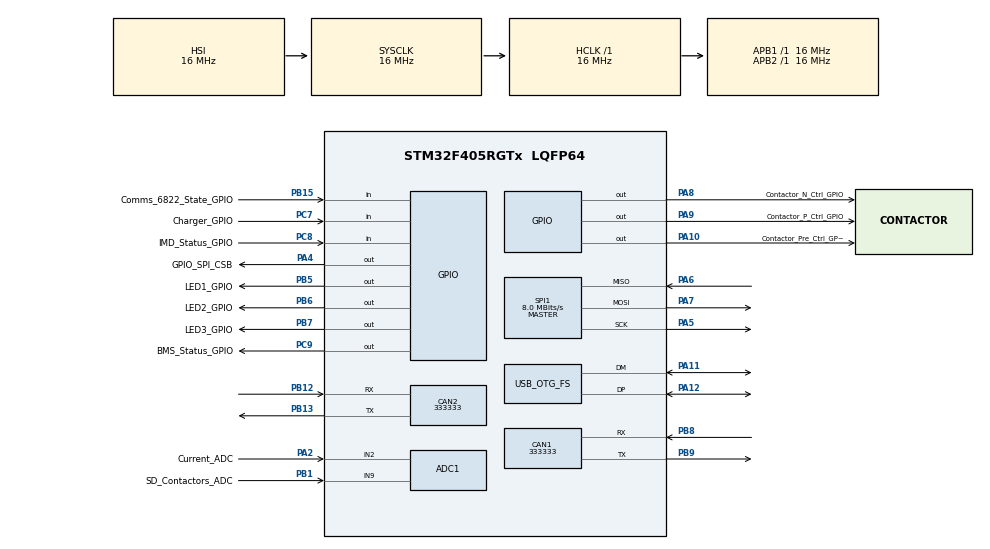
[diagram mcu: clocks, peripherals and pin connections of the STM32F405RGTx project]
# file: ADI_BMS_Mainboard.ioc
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ADC1.Channel-6\#ChannelRegularConversion=ADC_CHANNEL_2
ADC1.NbrOfConversionFlag=1
ADC1.Rank-6\#ChannelRegularConversion=1
ADC1.SamplingTime-6\#ChannelRegularConversion=ADC_SAMPLETIME_3CYCLES
ADC1.master=1
CAN1.CalculateBaudRate=333333
CAN1.CalculateTimeBit=3000
CAN1.CalculateTimeQuantum=1000.0
CAN2.CalculateBaudRate=333333
CAN2.CalculateTimeBit=3000
CAN2.CalculateTimeQuantum=1000.0
Mcu.Family=STM32F4
Mcu.Name=STM32F405RGTx
Mcu.Package=LQFP64
NVIC.OTG_FS_IRQn=true\:0\:0\:false\:false\:true\:false\:true\:true
NVIC.PriorityGroup=NVIC_PRIORITYGROUP_4
PA10.GPIO_Label=Contactor_Pre_Ctrl_GPIO
PA10.Signal=GPIO_Output
PA11.Mode=Device_Only
PA11.Signal=USB_OTG_FS_DM
PA12.Mode=Device_Only
PA12.Signal=USB_OTG_FS_DP
PA13.Mode=Trace_Asynchronous_SW
PA13.Signal=SYS_JTMS-SWDIO
PA14.Mode=Trace_Asynchronous_SW
PA14.Signal=SYS_JTCK-SWCLK
PA2.GPIO_Label=Current_ADC
PA2.Signal=ADCx_IN2
PA4.GPIO_Label=GPIO_SPI_CSB
PA4.Signal=GPIO_Output
PA5.Mode=Full_Duplex_Master
PA5.Signal=SPI1_SCK
PA6.Mode=Full_Duplex_Master
PA6.Signal=SPI1_MISO
PA7.Mode=Full_Duplex_Master
PA7.Signal=SPI1_MOSI
PA8.GPIO_Label=Contactor_N_Ctrl_GPIO
PA8.Signal=GPIO_Output
PA9.GPIO_Label=Contactor_P_Ctrl_GPIO
PA9.Signal=GPIO_Output
PB1.GPIO_Label=SD_Contactors_ADC
PB1.Signal=ADCx_IN9
PB12.Mode=CAN_Activate
PB12.Signal=CAN2_RX
PB13.Mode=CAN_Activate
PB13.Signal=CAN2_TX
PB15.GPIO_Label=Comms_6822_State_GPIO
PB15.Signal=GPIO_Input
PB3.Mode=Trace_Asynchronous_SW
PB3.Signal=SYS_JTDO-SWO
PB5.GPIO_Label=LED1_GPIO
PB5.Signal=GPIO_Output
PB6.GPIO_Label=LED2_GPIO
PB6.Signal=GPIO_Output
PB7.GPIO_Label=LED3_GPIO
PB7.Signal=GPIO_Output
PB8.Mode=CAN_Activate
PB8.Signal=CAN1_RX
PB9.Mode=CAN_Activate
PB9.Signal=CAN1_TX
PC7.GPIO_Label=Charger_GPIO
PC7.Signal=GPIO_Input
PC8.GPIO_Label=IMD_Status_GPIO
PC8.Signal=GPIO_Input
PC9.GPIO_Label=BMS_Status_GPIO
PC9.Signal=GPIO_Output
PH0-OSC_IN.Mode=HSE-External-Oscillator
PH0-OSC_IN.Signal=RCC_OSC_IN
PH1-OSC_OUT.Mode=HSE-External-Oscillator
PH1-OSC_OUT.Signal=RCC_OSC_OUT
ProjectManager.HeapSize=0x200
ProjectManager.StackSize=0x400
ProjectManager.TargetToolchain=STM32CubeIDE
RCC.48MHZClocksFreq_Value=48000000
RCC.AHBFreq_Value=16000000
RCC.APB1Freq_Value=16000000
RCC.APB2Freq_Value=16000000
RCC.CortexFreq_Value=16000000
RCC.HSE_VALUE=25000000
RCC.HSI_VALUE=16000000
RCC.LSE_VALUE=32768
RCC.PLLM=15
RCC.PLLN=144
RCC.PLLQ=5
RCC.SYSCLKFreq_VALUE=16000000
RCC.VCOOutputFreq_Value=240000000
SH.ADCx_IN2.0=ADC1_IN2,IN2
SH.ADCx_IN9.0=ADC1_IN9,IN9
SPI1.CalculateBaudRate=8.0 MBits/s
SPI1.Direction=SPI_DIRECTION_2LINES
SPI1.Mode=SPI_MODE_MASTER
SPI1.VirtualType=VM_MASTER
USB_DEVICE.CLASS_NAME_FS=CDC
USB_DEVICE.VirtualMode-CDC_FS=Cdc
USB_DEVICE.VirtualModeFS=Cdc_FS
USB_OTG_FS.VirtualMode=Device_Only
VP_TIM2_VS_ClockSourceINT.Mode=Internal
VP_USB_DEVICE_VS_USB_DEVICE_CDC_FS.Mode=CDC_FS
board=custom

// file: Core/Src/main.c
/* USER CODE BEGIN Header */
/**
  ******************************************************************************
  * @file           : main.c
  * @brief          : Main program body
  ******************************************************************************
  * @attention
  *
  * Copyright (c) 2025 STMicroelectronics.
  * All rights reserved.
  *
  * This software is licensed under terms that can be found in the LICENSE file
  * in the root directory of this software component.
  * If no LICENSE file comes with this software, it is provided AS-IS.
  *
  ******************************************************************************
  */
/* USER CODE END Header */
#include "main.h"
#include "usb_device.h"

/* USER CODE BEGIN Includes */
#include "adBms_Application.h"
#include "usbd_cdc_if.h"
// CDC_Transmit_FS((uint8_t *) txBuf, strlen(txBuf)); // transmit data over usb ie for putty or hterm

/* USER CODE END Includes */

ADC_HandleTypeDef hadc1;

CAN_HandleTypeDef hcan1;
CAN_HandleTypeDef hcan2;

SPI_HandleTypeDef hspi1;

TIM_HandleTypeDef htim2;

void SystemClock_Config(void);
static void MX_GPIO_Init(void);
static void MX_ADC1_Init(void);
static void MX_CAN1_Init(void);
static void MX_CAN2_Init(void);
static void MX_SPI1_Init(void);
static void MX_TIM2_Init(void);

int main(void)
{

  /* MCU Configuration--------------------------------------------------------*/

  /* Reset of all peripherals, Initializes the Flash interface and the Systick. */
  HAL_Init();

  /* Configure the system clock */
  SystemClock_Config();

  /* Initialize all configured peripherals */
  MX_GPIO_Init();
  MX_ADC1_Init();
  MX_CAN1_Init();
  MX_CAN2_Init();
  MX_SPI1_Init();
  MX_USB_DEVICE_Init();
  MX_TIM2_Init();
  /* USER CODE BEGIN 2 */
  adbms_main();

  /* USER CODE END 2 */

  /* Infinite loop */
  while (1)
  {

  }
}

void SystemClock_Config(void)
{
  RCC_OscInitTypeDef RCC_OscInitStruct = {0};
  RCC_ClkInitTypeDef RCC_ClkInitStruct = {0};

  /** Configure the main internal regulator output voltage
  */
  __HAL_RCC_PWR_CLK_ENABLE();
  __HAL_PWR_VOLTAGESCALING_CONFIG(PWR_REGULATOR_VOLTAGE_SCALE1);

  /** Initializes the RCC Oscillators according to the specified parameters
  * in the RCC_OscInitTypeDef structure.
  */
  RCC_OscInitStruct.OscillatorType = RCC_OSCILLATORTYPE_HSI|RCC_OSCILLATORTYPE_HSE;
  RCC_OscInitStruct.HSEState = RCC_HSE_ON;
  RCC_OscInitStruct.HSIState = RCC_HSI_ON;
  RCC_OscInitStruct.HSICalibrationValue = RCC_HSICALIBRATION_DEFAULT;
  RCC_OscInitStruct.PLL.PLLState = RCC_PLL_ON;
  RCC_OscInitStruct.PLL.PLLSource = RCC_PLLSOURCE_HSE;
  RCC_OscInitStruct.PLL.PLLM = 15;
  RCC_OscInitStruct.PLL.PLLN = 144;
  RCC_OscInitStruct.PLL.PLLP = RCC_PLLP_DIV2;
  RCC_OscInitStruct.PLL.PLLQ = 5;
  if (HAL_RCC_OscConfig(&RCC_OscInitStruct) != HAL_OK)
  {
    Error_Handler();
  }

  /** Initializes the CPU, AHB and APB buses clocks
  */
  RCC_ClkInitStruct.ClockType = RCC_CLOCKTYPE_HCLK|RCC_CLOCKTYPE_SYSCLK
                              |RCC_CLOCKTYPE_PCLK1|RCC_CLOCKTYPE_PCLK2;
  RCC_ClkInitStruct.SYSCLKSource = RCC_SYSCLKSOURCE_HSI;
  RCC_ClkInitStruct.AHBCLKDivider = RCC_SYSCLK_DIV1;
  RCC_ClkInitStruct.APB1CLKDivider = RCC_HCLK_DIV1;
  RCC_ClkInitStruct.APB2CLKDivider = RCC_HCLK_DIV1;

  if (HAL_RCC_ClockConfig(&RCC_ClkInitStruct, FLASH_LATENCY_0) != HAL_OK)
  {
    Error_Handler();
  }
}

static void MX_ADC1_Init(void)
{

  ADC_ChannelConfTypeDef sConfig = {0};

  /** Configure the global features of the ADC (Clock, Resolution, Data Alignment and number of conversion)
  */
  hadc1.Instance = ADC1;
  hadc1.Init.ClockPrescaler = ADC_CLOCK_SYNC_PCLK_DIV2;
  hadc1.Init.Resolution = ADC_RESOLUTION_12B;
  hadc1.Init.ScanConvMode = DISABLE;
  hadc1.Init.ContinuousConvMode = DISABLE;
  hadc1.Init.DiscontinuousConvMode = DISABLE;
  hadc1.Init.ExternalTrigConvEdge = ADC_EXTERNALTRIGCONVEDGE_NONE;
  hadc1.Init.ExternalTrigConv = ADC_SOFTWARE_START;
  hadc1.Init.DataAlign = ADC_DATAALIGN_RIGHT;
  hadc1.Init.NbrOfConversion = 1;
  hadc1.Init.DMAContinuousRequests = DISABLE;
  hadc1.Init.EOCSelection = ADC_EOC_SINGLE_CONV;
  if (HAL_ADC_Init(&hadc1) != HAL_OK)
  {
    Error_Handler();
  }

  /** Configure for the selected ADC regular channel its corresponding rank in the sequencer and its sample time.
  */
  sConfig.Channel = ADC_CHANNEL_2;
  sConfig.Rank = 1;
  sConfig.SamplingTime = ADC_SAMPLETIME_3CYCLES;
  if (HAL_ADC_ConfigChannel(&hadc1, &sConfig) != HAL_OK)
  {
    Error_Handler();
  }

}

static void MX_CAN1_Init(void)
{

  hcan1.Instance = CAN1;
  hcan1.Init.Prescaler = 16;
  hcan1.Init.Mode = CAN_MODE_NORMAL;
  hcan1.Init.SyncJumpWidth = CAN_SJW_1TQ;
  hcan1.Init.TimeSeg1 = CAN_BS1_1TQ;
  hcan1.Init.TimeSeg2 = CAN_BS2_1TQ;
  hcan1.Init.TimeTriggeredMode = DISABLE;
  hcan1.Init.AutoBusOff = DISABLE;
  hcan1.Init.AutoWakeUp = DISABLE;
  hcan1.Init.AutoRetransmission = DISABLE;
  hcan1.Init.ReceiveFifoLocked = DISABLE;
  hcan1.Init.TransmitFifoPriority = DISABLE;
  if (HAL_CAN_Init(&hcan1) != HAL_OK)
  {
    Error_Handler();
  }

}

static void MX_CAN2_Init(void)
{

  hcan2.Instance = CAN2;
  hcan2.Init.Prescaler = 16;
  hcan2.Init.Mode = CAN_MODE_NORMAL;
  hcan2.Init.SyncJumpWidth = CAN_SJW_1TQ;
  hcan2.Init.TimeSeg1 = CAN_BS1_1TQ;
  hcan2.Init.TimeSeg2 = CAN_BS2_1TQ;
  hcan2.Init.TimeTriggeredMode = DISABLE;
  hcan2.Init.AutoBusOff = DISABLE;
  hcan2.Init.AutoWakeUp = DISABLE;
  hcan2.Init.AutoRetransmission = DISABLE;
  hcan2.Init.ReceiveFifoLocked = DISABLE;
  hcan2.Init.TransmitFifoPriority = DISABLE;
  if (HAL_CAN_Init(&hcan2) != HAL_OK)
  {
    Error_Handler();
  }

}

static void MX_SPI1_Init(void)
{

  /* SPI1 parameter configuration*/
  hspi1.Instance = SPI1;
  hspi1.Init.Mode = SPI_MODE_MASTER;
  hspi1.Init.Direction = SPI_DIRECTION_2LINES;
  hspi1.Init.DataSize = SPI_DATASIZE_8BIT;
  hspi1.Init.CLKPolarity = SPI_POLARITY_LOW;
  hspi1.Init.CLKPhase = SPI_PHASE_1EDGE;
  hspi1.Init.NSS = SPI_NSS_SOFT;
  hspi1.Init.BaudRatePrescaler = SPI_BAUDRATEPRESCALER_2;
  hspi1.Init.FirstBit = SPI_FIRSTBIT_MSB;
  hspi1.Init.TIMode = SPI_TIMODE_DISABLE;
  hspi1.Init.CRCCalculation = SPI_CRCCALCULATION_DISABLE;
  hspi1.Init.CRCPolynomial = 10;
  if (HAL_SPI_Init(&hspi1) != HAL_OK)
  {
    Error_Handler();
  }

}

static void MX_TIM2_Init(void)
{

  TIM_ClockConfigTypeDef sClockSourceConfig = {0};
  TIM_MasterConfigTypeDef sMasterConfig = {0};

  htim2.Instance = TIM2;
  htim2.Init.Prescaler = 0;
  htim2.Init.CounterMode = TIM_COUNTERMODE_UP;
  htim2.Init.Period = 4294967295;
  htim2.Init.ClockDivision = TIM_CLOCKDIVISION_DIV1;
  htim2.Init.AutoReloadPreload = TIM_AUTORELOAD_PRELOAD_DISABLE;
  if (HAL_TIM_Base_Init(&htim2) != HAL_OK)
  {
    Error_Handler();
  }
  sClockSourceConfig.ClockSource = TIM_CLOCKSOURCE_INTERNAL;
  if (HAL_TIM_ConfigClockSource(&htim2, &sClockSourceConfig) != HAL_OK)
  {
    Error_Handler();
  }
  sMasterConfig.MasterOutputTrigger = TIM_TRGO_RESET;
  sMasterConfig.MasterSlaveMode = TIM_MASTERSLAVEMODE_DISABLE;
  if (HAL_TIMEx_MasterConfigSynchronization(&htim2, &sMasterConfig) != HAL_OK)
  {
    Error_Handler();
  }

}

static void MX_GPIO_Init(void)
{
  GPIO_InitTypeDef GPIO_InitStruct = {0};

  /* GPIO Ports Clock Enable */
  __HAL_RCC_GPIOH_CLK_ENABLE();
  __HAL_RCC_GPIOA_CLK_ENABLE();
  __HAL_RCC_GPIOB_CLK_ENABLE();
  __HAL_RCC_GPIOC_CLK_ENABLE();

  /*Configure GPIO pin Output Level */
  HAL_GPIO_WritePin(GPIOA, GPIO_SPI_CSB_Pin|Contactor_N_Ctrl_GPIO_Pin|Contactor_P_Ctrl_GPIO_Pin|Contactor_Pre_Ctrl_GPIO_Pin, GPIO_PIN_RESET);

  /*Configure GPIO pin Output Level */
  HAL_GPIO_WritePin(BMS_Status_GPIO_GPIO_Port, BMS_Status_GPIO_Pin, GPIO_PIN_RESET);

  /*Configure GPIO pin Output Level */
  HAL_GPIO_WritePin(GPIOB, LED1_GPIO_Pin|LED2_GPIO_Pin|LED3_GPIO_Pin, GPIO_PIN_RESET);

  /*Configure GPIO pins : GPIO_SPI_CSB_Pin Contactor_N_Ctrl_GPIO_Pin Contactor_P_Ctrl_GPIO_Pin Contactor_Pre_Ctrl_GPIO_Pin */
  GPIO_InitStruct.Pin = GPIO_SPI_CSB_Pin|Contactor_N_Ctrl_GPIO_Pin|Contactor_P_Ctrl_GPIO_Pin|Contactor_Pre_Ctrl_GPIO_Pin;
  GPIO_InitStruct.Mode = GPIO_MODE_OUTPUT_PP;
  GPIO_InitStruct.Pull = GPIO_NOPULL;
  GPIO_InitStruct.Speed = GPIO_SPEED_FREQ_LOW;
  HAL_GPIO_Init(GPIOA, &GPIO_InitStruct);

  /*Configure GPIO pin : Comms_6822_State_GPIO_Pin */
  GPIO_InitStruct.Pin = Comms_6822_State_GPIO_Pin;
  GPIO_InitStruct.Mode = GPIO_MODE_INPUT;
  GPIO_InitStruct.Pull = GPIO_NOPULL;
  HAL_GPIO_Init(Comms_6822_State_GPIO_GPIO_Port, &GPIO_InitStruct);

  /*Configure GPIO pins : Charger_GPIO_Pin IMD_Status_GPIO_Pin */
  GPIO_InitStruct.Pin = Charger_GPIO_Pin|IMD_Status_GPIO_Pin;
  GPIO_InitStruct.Mode = GPIO_MODE_INPUT;
  GPIO_InitStruct.Pull = GPIO_NOPULL;
  HAL_GPIO_Init(GPIOC, &GPIO_InitStruct);

  /*Configure GPIO pin : BMS_Status_GPIO_Pin */
  GPIO_InitStruct.Pin = BMS_Status_GPIO_Pin;
  GPIO_InitStruct.Mode = GPIO_MODE_OUTPUT_PP;
  GPIO_InitStruct.Pull = GPIO_NOPULL;
  GPIO_InitStruct.Speed = GPIO_SPEED_FREQ_LOW;
  HAL_GPIO_Init(BMS_Status_GPIO_GPIO_Port, &GPIO_InitStruct);

  /*Configure GPIO pins : LED1_GPIO_Pin LED2_GPIO_Pin LED3_GPIO_Pin */
  GPIO_InitStruct.Pin = LED1_GPIO_Pin|LED2_GPIO_Pin|LED3_GPIO_Pin;
  GPIO_InitStruct.Mode = GPIO_MODE_OUTPUT_PP;
  GPIO_InitStruct.Pull = GPIO_NOPULL;
  GPIO_InitStruct.Speed = GPIO_SPEED_FREQ_LOW;
  HAL_GPIO_Init(GPIOB, &GPIO_InitStruct);

}

void Error_Handler(void)
{
  __disable_irq();
  while (1)
  {
  }
}
